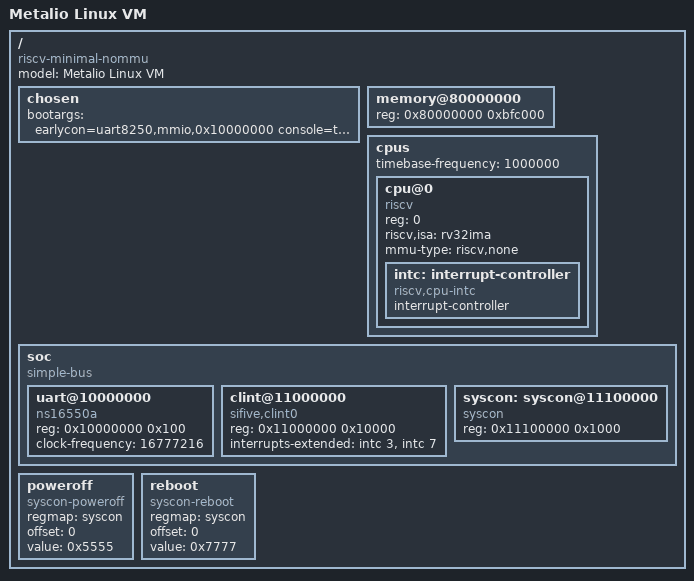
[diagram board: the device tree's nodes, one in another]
/dts-v1/;
/ {
    #address-cells = <1>;
    #size-cells = <1>;
    compatible = "riscv-minimal-nommu";
    model = "Metalio Linux VM";
    chosen {
        bootargs = "earlycon=uart8250,mmio,0x10000000 console=ttyS0";
    };
    memory@80000000 {
        device_type = "memory";
        /* 12 MiB 虚拟内存，末尾 16 KiB 留给设备树。 */
        reg = <0x80000000 0xbfc000>;
    };
    cpus {
        #address-cells = <1>;
        #size-cells = <0>;
        timebase-frequency = <1000000>;
        cpu@0 {
            device_type = "cpu";
            reg = <0>;
            compatible = "riscv";
            riscv,isa = "rv32ima";
            mmu-type = "riscv,none";
            intc: interrupt-controller {
                #interrupt-cells = <1>;
                interrupt-controller;
                compatible = "riscv,cpu-intc";
            };
        };
    };
    soc {
        #address-cells = <1>;
        #size-cells = <1>;
        compatible = "simple-bus";
        ranges;
        uart@10000000 {
            compatible = "ns16550a";
            reg = <0x10000000 0x100>;
            clock-frequency = <16777216>;
        };
        clint@11000000 {
            compatible = "sifive,clint0", "riscv,clint0";
            reg = <0x11000000 0x10000>;
            interrupts-extended = <&intc 3 &intc 7>;
        };
        syscon: syscon@11100000 {
            compatible = "syscon";
            reg = <0x11100000 0x1000>;
        };
    };
    poweroff {
        compatible = "syscon-poweroff";
        regmap = <&syscon>;
        offset = <0>;
        value = <0x5555>;
    };
    reboot {
        compatible = "syscon-reboot";
        regmap = <&syscon>;
        offset = <0>;
        value = <0x7777>;
    };
};
